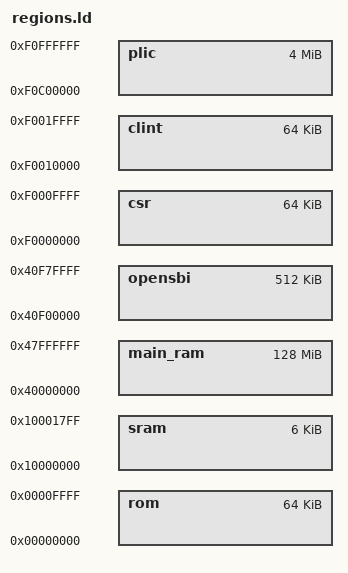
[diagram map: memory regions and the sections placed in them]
MEMORY {
	opensbi : ORIGIN = 0x40f00000, LENGTH = 0x00080000
	plic : ORIGIN = 0xf0c00000, LENGTH = 0x00400000
	clint : ORIGIN = 0xf0010000, LENGTH = 0x00010000
	rom : ORIGIN = 0x00000000, LENGTH = 0x00010000
	sram : ORIGIN = 0x10000000, LENGTH = 0x00001800
	main_ram : ORIGIN = 0x40000000, LENGTH = 0x08000000
	csr : ORIGIN = 0xf0000000, LENGTH = 0x00010000
}
